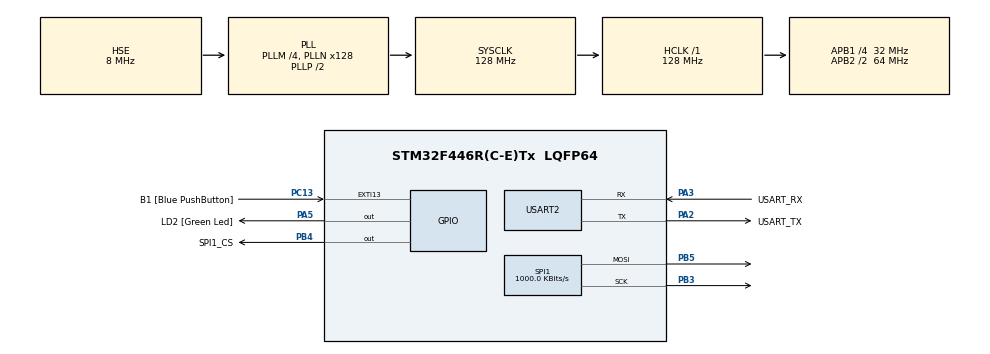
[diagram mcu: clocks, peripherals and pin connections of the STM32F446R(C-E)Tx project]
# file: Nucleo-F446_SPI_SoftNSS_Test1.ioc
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Mcu.Family=STM32F4
Mcu.Name=STM32F446R(C-E)Tx
Mcu.Package=LQFP64
NVIC.PriorityGroup=NVIC_PRIORITYGROUP_0
PA13.GPIO_Label=TMS
PA13.Mode=Serial_Wire
PA13.Signal=SYS_JTMS-SWDIO
PA14.GPIO_Label=TCK
PA14.Mode=Serial_Wire
PA14.Signal=SYS_JTCK-SWCLK
PA2.GPIO_Label=USART_TX
PA2.Mode=Asynchronous
PA2.Signal=USART2_TX
PA3.GPIO_Label=USART_RX
PA3.Mode=Asynchronous
PA3.Signal=USART2_RX
PA5.GPIO_Label=LD2 [Green Led]
PA5.Signal=GPIO_Output
PB3.Mode=TX_Only_Simplex_Unidirect_Master
PB3.Signal=SPI1_SCK
PB4.GPIO_Label=SPI1_CS
PB4.GPIO_Speed=GPIO_SPEED_FREQ_MEDIUM
PB4.PinState=GPIO_PIN_SET
PB4.Signal=GPIO_Output
PB5.Mode=TX_Only_Simplex_Unidirect_Master
PB5.Signal=SPI1_MOSI
PC13.GPIO_Label=B1 [Blue PushButton]
PC13.GPIO_ModeDefaultEXTI=GPIO_MODE_IT_FALLING
PC13.Signal=GPXTI13
PC14-OSC32_IN.Mode=LSE-External-Oscillator
PC14-OSC32_IN.Signal=RCC_OSC32_IN
PC15-OSC32_OUT.Mode=LSE-External-Oscillator
PC15-OSC32_OUT.Signal=RCC_OSC32_OUT
PH0-OSC_IN.Mode=HSE-External-Oscillator
PH0-OSC_IN.Signal=RCC_OSC_IN
PH1-OSC_OUT.Mode=HSE-External-Oscillator
PH1-OSC_OUT.Signal=RCC_OSC_OUT
ProjectManager.HeapSize=0x200
ProjectManager.StackSize=0x400
ProjectManager.TargetToolchain=SW4STM32
RCC.48MHZClocksFreq_Value=84000000
RCC.AHBFreq_Value=128000000
RCC.APB1CLKDivider=RCC_HCLK_DIV4
RCC.APB1Freq_Value=32000000
RCC.APB1TimFreq_Value=64000000
RCC.APB2CLKDivider=RCC_HCLK_DIV2
RCC.APB2Freq_Value=64000000
RCC.APB2TimFreq_Value=128000000
RCC.CortexFreq_Value=128000000
RCC.FLatency-AdvancedSettings=FLASH_LATENCY_4
RCC.HCLKFreq_Value=128000000
RCC.HSE_VALUE=8000000
RCC.HSI_VALUE=16000000
RCC.PLLM=4
RCC.PLLN=128
RCC.PLLSourceVirtual=RCC_PLLSOURCE_HSE
RCC.SYSCLKFreq_VALUE=128000000
RCC.SYSCLKSource=RCC_SYSCLKSOURCE_PLLCLK
RCC.USBFreq_Value=128000000
RCC.VCOOutputFreq_Value=256000000
SPI1.BaudRatePrescaler=SPI_BAUDRATEPRESCALER_64
SPI1.CalculateBaudRate=1000.0 KBits/s
SPI1.Direction=SPI_DIRECTION_2LINES
SPI1.Mode=SPI_MODE_MASTER
SPI1.VirtualType=VM_MASTER
USART2.VirtualMode=VM_ASYNC
board=NUCLEO-F446RE

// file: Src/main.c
/* USER CODE BEGIN Header */
/**
  ******************************************************************************
  * @file           : main.c
  * @brief          : Main program body
  ******************************************************************************
  * @attention
  *
  * <h2><center>&copy; Copyright (c) 2019 STMicroelectronics.
  * All rights reserved.</center></h2>
  *
  * This software component is licensed by ST under BSD 3-Clause license,
  * the "License"; You may not use this file except in compliance with the
  * License. You may obtain a copy of the License at:
  *                        opensource.org/licenses/BSD-3-Clause
  *
  ******************************************************************************
  */
/* USER CODE END Header */

#include "main.h"

SPI_HandleTypeDef hspi1;

UART_HandleTypeDef huart2;

void SystemClock_Config(void);
static void MX_GPIO_Init(void);
static void MX_USART2_UART_Init(void);
static void MX_SPI1_Init(void);

int main(void)
{

  /* MCU Configuration--------------------------------------------------------*/

  /* Reset of all peripherals, Initializes the Flash interface and the Systick. */
  HAL_Init();

  /* Configure the system clock */
  SystemClock_Config();

  /* Initialize all configured peripherals */
  MX_GPIO_Init();
  MX_USART2_UART_Init();
  MX_SPI1_Init();

  /* Infinite loop */
  while (1)
  {

    /* USER CODE BEGIN 3 */
	uint8_t data[2] = { 0x55, 0xAA };
	HAL_GPIO_WritePin(SPI1_CS_GPIO_Port, SPI1_CS_Pin, GPIO_PIN_RESET);
	if (HAL_SPI_Transmit(&hspi1, data, 2, 100) != HAL_OK) {
		Error_Handler();
	}
	HAL_GPIO_WritePin(SPI1_CS_GPIO_Port, SPI1_CS_Pin, GPIO_PIN_SET);
  }
  /* USER CODE END 3 */
}

void SystemClock_Config(void)
{
  RCC_OscInitTypeDef RCC_OscInitStruct = {0};
  RCC_ClkInitTypeDef RCC_ClkInitStruct = {0};

  /** Configure the main internal regulator output voltage
  */
  __HAL_RCC_PWR_CLK_ENABLE();
  __HAL_PWR_VOLTAGESCALING_CONFIG(PWR_REGULATOR_VOLTAGE_SCALE2);
  /** Initializes the CPU, AHB and APB busses clocks
  */
  RCC_OscInitStruct.OscillatorType = RCC_OSCILLATORTYPE_HSE;
  RCC_OscInitStruct.HSEState = RCC_HSE_ON;
  RCC_OscInitStruct.PLL.PLLState = RCC_PLL_ON;
  RCC_OscInitStruct.PLL.PLLSource = RCC_PLLSOURCE_HSE;
  RCC_OscInitStruct.PLL.PLLM = 4;
  RCC_OscInitStruct.PLL.PLLN = 128;
  RCC_OscInitStruct.PLL.PLLP = RCC_PLLP_DIV2;
  RCC_OscInitStruct.PLL.PLLQ = 2;
  RCC_OscInitStruct.PLL.PLLR = 2;
  if (HAL_RCC_OscConfig(&RCC_OscInitStruct) != HAL_OK)
  {
    Error_Handler();
  }
  /** Initializes the CPU, AHB and APB busses clocks
  */
  RCC_ClkInitStruct.ClockType = RCC_CLOCKTYPE_HCLK|RCC_CLOCKTYPE_SYSCLK
                              |RCC_CLOCKTYPE_PCLK1|RCC_CLOCKTYPE_PCLK2;
  RCC_ClkInitStruct.SYSCLKSource = RCC_SYSCLKSOURCE_PLLCLK;
  RCC_ClkInitStruct.AHBCLKDivider = RCC_SYSCLK_DIV1;
  RCC_ClkInitStruct.APB1CLKDivider = RCC_HCLK_DIV4;
  RCC_ClkInitStruct.APB2CLKDivider = RCC_HCLK_DIV2;

  if (HAL_RCC_ClockConfig(&RCC_ClkInitStruct, FLASH_LATENCY_4) != HAL_OK)
  {
    Error_Handler();
  }
}

static void MX_SPI1_Init(void)
{

  /* SPI1 parameter configuration*/
  hspi1.Instance = SPI1;
  hspi1.Init.Mode = SPI_MODE_MASTER;
  hspi1.Init.Direction = SPI_DIRECTION_2LINES;
  hspi1.Init.DataSize = SPI_DATASIZE_8BIT;
  hspi1.Init.CLKPolarity = SPI_POLARITY_LOW;
  hspi1.Init.CLKPhase = SPI_PHASE_1EDGE;
  hspi1.Init.NSS = SPI_NSS_SOFT;
  hspi1.Init.BaudRatePrescaler = SPI_BAUDRATEPRESCALER_64;
  hspi1.Init.FirstBit = SPI_FIRSTBIT_MSB;
  hspi1.Init.TIMode = SPI_TIMODE_DISABLE;
  hspi1.Init.CRCCalculation = SPI_CRCCALCULATION_DISABLE;
  hspi1.Init.CRCPolynomial = 10;
  if (HAL_SPI_Init(&hspi1) != HAL_OK)
  {
    Error_Handler();
  }

}

static void MX_USART2_UART_Init(void)
{

  huart2.Instance = USART2;
  huart2.Init.BaudRate = 115200;
  huart2.Init.WordLength = UART_WORDLENGTH_8B;
  huart2.Init.StopBits = UART_STOPBITS_1;
  huart2.Init.Parity = UART_PARITY_NONE;
  huart2.Init.Mode = UART_MODE_TX_RX;
  huart2.Init.HwFlowCtl = UART_HWCONTROL_NONE;
  huart2.Init.OverSampling = UART_OVERSAMPLING_16;
  if (HAL_UART_Init(&huart2) != HAL_OK)
  {
    Error_Handler();
  }

}

static void MX_GPIO_Init(void)
{
  GPIO_InitTypeDef GPIO_InitStruct = {0};

  /* GPIO Ports Clock Enable */
  __HAL_RCC_GPIOC_CLK_ENABLE();
  __HAL_RCC_GPIOH_CLK_ENABLE();
  __HAL_RCC_GPIOA_CLK_ENABLE();
  __HAL_RCC_GPIOB_CLK_ENABLE();

  /*Configure GPIO pin Output Level */
  HAL_GPIO_WritePin(LD2_GPIO_Port, LD2_Pin, GPIO_PIN_RESET);

  /*Configure GPIO pin Output Level */
  HAL_GPIO_WritePin(SPI1_CS_GPIO_Port, SPI1_CS_Pin, GPIO_PIN_SET);

  /*Configure GPIO pin : B1_Pin */
  GPIO_InitStruct.Pin = B1_Pin;
  GPIO_InitStruct.Mode = GPIO_MODE_IT_FALLING;
  GPIO_InitStruct.Pull = GPIO_NOPULL;
  HAL_GPIO_Init(B1_GPIO_Port, &GPIO_InitStruct);

  /*Configure GPIO pin : LD2_Pin */
  GPIO_InitStruct.Pin = LD2_Pin;
  GPIO_InitStruct.Mode = GPIO_MODE_OUTPUT_PP;
  GPIO_InitStruct.Pull = GPIO_NOPULL;
  GPIO_InitStruct.Speed = GPIO_SPEED_FREQ_LOW;
  HAL_GPIO_Init(LD2_GPIO_Port, &GPIO_InitStruct);

  /*Configure GPIO pin : SPI1_CS_Pin */
  GPIO_InitStruct.Pin = SPI1_CS_Pin;
  GPIO_InitStruct.Mode = GPIO_MODE_OUTPUT_PP;
  GPIO_InitStruct.Pull = GPIO_NOPULL;
  GPIO_InitStruct.Speed = GPIO_SPEED_FREQ_MEDIUM;
  HAL_GPIO_Init(SPI1_CS_GPIO_Port, &GPIO_InitStruct);

}

void Error_Handler(void)
{
}

/************************ (C) COPYRIGHT STMicroelectronics *****END OF FILE****/
